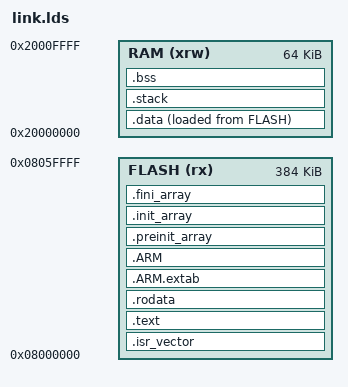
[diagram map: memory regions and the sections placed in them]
/*
******************************************************************************
**

**  File        : LinkerScript.ld
**
**  Author      : Puya_HC
**
**  Abstract    : Linker script for PY32F403xD series
**                384Kbytes FLASH and 64Kbytes RAM
**
**                Set heap size, stack size and stack location according
**                to application requirements.
**
**                Set memory bank area and size if external memory is used.
**
**  Target      : Puya PY32
**
**  Distribution: The file is distributed “as is,” without any warranty
**                of any kind.
**
*****************************************************************************
** @attention
**
** <h2><center>&copy; COPYRIGHT(c) 2019 Puya Semiconductor</center></h2>
**
** Redistribution and use in source and binary forms, with or without modification,
** are permitted provided that the following conditions are met:
**   1. Redistributions of source code must retain the above copyright notice,
**      this list of conditions and the following disclaimer.
**   2. Redistributions in binary form must reproduce the above copyright notice,
**      this list of conditions and the following disclaimer in the documentation
**      and/or other materials provided with the distribution.
**   3. Neither the name of Puya Semiconductor nor the names of its contributors
**      may be used to endorse or promote products derived from this software
**      without specific prior written permission.
**
** THIS SOFTWARE IS PROVIDED BY THE COPYRIGHT HOLDERS AND CONTRIBUTORS "AS IS"
** AND ANY EXPRESS OR IMPLIED WARRANTIES, INCLUDING, BUT NOT LIMITED TO, THE
** IMPLIED WARRANTIES OF MERCHANTABILITY AND FITNESS FOR A PARTICULAR PURPOSE ARE
** DISCLAIMED. IN NO EVENT SHALL THE COPYRIGHT HOLDER OR CONTRIBUTORS BE LIABLE
** FOR ANY DIRECT, INDIRECT, INCIDENTAL, SPECIAL, EXEMPLARY, OR CONSEQUENTIAL
** DAMAGES (INCLUDING, BUT NOT LIMITED TO, PROCUREMENT OF SUBSTITUTE GOODS OR
** SERVICES; LOSS OF USE, DATA, OR PROFITS; OR BUSINESS INTERRUPTION) HOWEVER
** CAUSED AND ON ANY THEORY OF LIABILITY, WHETHER IN CONTRACT, STRICT LIABILITY,
** OR TORT (INCLUDING NEGLIGENCE OR OTHERWISE) ARISING IN ANY WAY OUT OF THE USE
** OF THIS SOFTWARE, EVEN IF ADVISED OF THE POSSIBILITY OF SUCH DAMAGE.
**
*****************************************************************************
*/

/* Entry Point */
ENTRY(Reset_Handler)

_system_stack_size = 0x400;

/* Specify the memory areas */
MEMORY
{
RAM (xrw)      : ORIGIN = 0x20000000, LENGTH = 64K
FLASH (rx)      : ORIGIN = 0x8000000, LENGTH = 384K
}

/* Define output sections */
SECTIONS
{
  /* The startup code goes first into FLASH */
  .isr_vector :
  {
    . = ALIGN(4);
    KEEP(*(.isr_vector)) /* Startup code */
    . = ALIGN(4);
  } >FLASH

  /* The program code and other data goes into FLASH */
  .text :
  {
    . = ALIGN(4);
    *(.text)           /* .text sections (code) */
    *(.text*)          /* .text* sections (code) */
    *(.glue_7)         /* glue arm to thumb code */
    *(.glue_7t)        /* glue thumb to arm code */
    *(.eh_frame)

    KEEP (*(.init))
    KEEP (*(.fini))

    . = ALIGN(4);
    _etext = .;        /* define a global symbols at end of code */
  } >FLASH

  /* Constant data goes into FLASH */
  .rodata :
  {
    . = ALIGN(4);
    *(.rodata)         /* .rodata sections (constants, strings, etc.) */
    *(.rodata*)        /* .rodata* sections (constants, strings, etc.) */
    . = ALIGN(4);

    __fsymtab_start = .;
    KEEP(*(FSymTab))
    __fsymtab_end = .;

    . = ALIGN(4);
    __vsymtab_start = .;
    KEEP(*(VSymTab))
    __vsymtab_end = .;

    . = ALIGN(4);
    __rt_init_start = .;
    KEEP(*(SORT(.rti_fn*)))
    __rt_init_end = .;

    . = ALIGN(4);
    __rt_utest_tc_tab_start = .;
    KEEP(*(UtestTcTab))
    __rt_utest_tc_tab_end = .;
    . = ALIGN(4);
  } >FLASH

  .ARM.extab   : { *(.ARM.extab* .gnu.linkonce.armextab.*) } >FLASH
  .ARM : {
    __exidx_start = .;
    *(.ARM.exidx*)
    __exidx_end = .;
  } >FLASH

  .preinit_array     :
  {
    PROVIDE_HIDDEN (__preinit_array_start = .);
    KEEP (*(.preinit_array*))
    PROVIDE_HIDDEN (__preinit_array_end = .);
  } >FLASH
  .init_array :
  {
    . = ALIGN(4);
    __ctors_start__ = .;
    PROVIDE_HIDDEN (__init_array_start = .);
    KEEP (*(SORT(.init_array.*)))
    KEEP (*(.init_array*))
    PROVIDE_HIDDEN (__init_array_end = .);
    __ctors_end__ = .;
  } >FLASH
  .fini_array :
  {
    PROVIDE_HIDDEN (__fini_array_start = .);
    KEEP (*(SORT(.fini_array.*)))
    KEEP (*(.fini_array*))
    PROVIDE_HIDDEN (__fini_array_end = .);
  } >FLASH

  /* used by the startup to initialize data */
  _sidata = LOADADDR(.data);

  /* Initialized data sections goes into RAM, load LMA copy after code */
  .data :
  {
    . = ALIGN(4);
    _sdata = .;        /* create a global symbol at data start */
    *(.data)           /* .data sections */
    *(.data*)          /* .data* sections */
    *(.got)            /* global offset table */
    *(.got*)
    . = ALIGN(4);
    _edata = .;        /* define a global symbol at data end */
  } >RAM AT> FLASH

  .stack (NOLOAD) : ALIGN(8)
  {
    _sstack = .;
    . = . + _system_stack_size;
    . = ALIGN(8);
    _estack = .;
  } >RAM

  /* Uninitialized data section */
  .bss (NOLOAD) : ALIGN(4)
  {
    _sbss = .;
    __bss_start__ = _sbss;
    *(.bss)
    *(.bss*)
    *(COMMON)

    . = ALIGN(8);
    _ebss = .;         /* define a global symbol at bss end */
    __bss_end__ = _ebss;
  } >RAM

  _end = .;
  PROVIDE(end = .);

  /DISCARD/ :
  {
    *(.note.GNU-stack)
  }

  .ARM.attributes 0 : { *(.ARM.attributes) }
}
